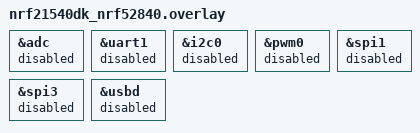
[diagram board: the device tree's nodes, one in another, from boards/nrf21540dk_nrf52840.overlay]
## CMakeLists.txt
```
#
# Copyright (c) 2021 Nordic Semiconductor ASA
#
# SPDX-License-Identifier: LicenseRef-Nordic-5-Clause
#

cmake_minimum_required(VERSION 3.20.0)

find_package(Zephyr HINTS $ENV{ZEPHYR_BASE})

project(matter-light-switch)

# Enable GNU STD support.
include(${ZEPHYR_CONNECTEDHOMEIP_MODULE_DIR}/config/nrfconnect/app/enable-gnu-std.cmake)

# NORDIC SDK APP START

# Include all source files that are located in the Matter common directory.
include(${ZEPHYR_NRF_MODULE_DIR}/samples/matter/common/cmake/source_common.cmake)

# Include Data Model utils
include(${ZEPHYR_NRF_MODULE_DIR}/samples/matter/common/cmake/data_model.cmake)

include(${ZEPHYR_NRF_MODULE_DIR}/samples/matter/common/cmake/zap_helpers.cmake)
ncs_get_zap_parent_dir(ZAP_PARENT_DIR)

target_include_directories(app PRIVATE
    src
    ${ZAP_PARENT_DIR}
)

target_compile_options(app PRIVATE -Wno-deprecated-declarations)

target_sources(app PRIVATE
    src/app_task.cpp
    src/light_switch.cpp
    src/main.cpp
    src/shell_commands.cpp
    ${ZEPHYR_NRF_MODULE_DIR}/samples/matter/common/src/binding/binding_handler.cpp
)

ncs_configure_data_model()
# NORDIC SDK APP END
```

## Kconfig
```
#
# Copyright (c) 2022 Nordic Semiconductor
#
# SPDX-License-Identifier: LicenseRef-Nordic-5-Clause
#
mainmenu "Matter nRF Connect Light Switch Example Application"

config STATE_LEDS
	bool "Use LEDs to indicate the device state"
	default y
	help
	  Use LEDs to render the current state of the device such as the progress of commissioning of
	  the device into a network or the factory reset initiation. Note that setting this option to
	  'n' does not disable the LED indicating the state of the simulated bolt.

# Sample configuration used for Thread networking
if OPENTHREAD

choice OPENTHREAD_NORDIC_LIBRARY_CONFIGURATION
	default OPENTHREAD_NORDIC_LIBRARY_MTD
endchoice

choice OPENTHREAD_DEVICE_TYPE
	default OPENTHREAD_MTD
endchoice

config CHIP_ENABLE_ICD_SUPPORT
	default y

# Reduce Thread TX output power to 0 dBm for SED device
config OPENTHREAD_DEFAULT_TX_POWER
	int
	default 0

endif # OPENTHREAD

if CHIP_WIFI

config NRF_WIFI_LOW_POWER
	default y

endif # CHIP_WIFI

# Enable Read Client functionality for all build configurations.
config CHIP_ENABLE_READ_CLIENT
	default y

source "${ZEPHYR_CONNECTEDHOMEIP_MODULE_DIR}/config/nrfconnect/chip-module/Kconfig.features"
source "${ZEPHYR_CONNECTEDHOMEIP_MODULE_DIR}/config/nrfconnect/chip-module/Kconfig.defaults"
source "${ZEPHYR_NRF_MODULE_DIR}/samples/matter/common/src/Kconfig"
source "Kconfig.zephyr"
```

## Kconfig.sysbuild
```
#
# Copyright (c) 2023 Nordic Semiconductor ASA
#
# SPDX-License-Identifier: LicenseRef-Nordic-5-Clause
#

config WIFI_NRF70
	default y if BOARD_NRF7002DK

#### Radio core selection
config NRF_DEFAULT_IPC_RADIO
	default y

# Enable IEEE802.15.4 serialization to network core
# This config automatically pulls in the `overlay-802154.conf` in the ipc_radio image
config NETCORE_IPC_RADIO_IEEE802154
	default y if SOC_SERIES_NRF53X && !WIFI_NRF70

# Enable Bluetooth serialization to network core
# This config automatically pulls in the `overlay-bt_hci_ipc.conf` in the ipc_radio image
config NETCORE_IPC_RADIO_BT_HCI_IPC
	default y if SOC_SERIES_NRF53X

#### Bootloader
choice BOOTLOADER
	default BOOTLOADER_MCUBOOT if !BOARD_NRF21540DK
endchoice

if BOOTLOADER_MCUBOOT

#### DFU multi-image support
config DFU_MULTI_IMAGE_PACKAGE_BUILD
	default y

config DFU_MULTI_IMAGE_PACKAGE_APP
	default y

config PM_EXTERNAL_FLASH_MCUBOOT_SECONDARY
	default y

#### DFU network core configuration
if SOC_SERIES_NRF53X

config MCUBOOT_UPDATEABLE_IMAGES
	default 2

choice MCUBOOT_MODE
	default MCUBOOT_MODE_OVERWRITE_ONLY
endchoice

choice BOOT_SIGNATURE_TYPE
	default BOOT_SIGNATURE_TYPE_RSA
endchoice

config SECURE_BOOT_NETCORE
	default y

config NETCORE_APP_UPDATE
	default y

config DFU_MULTI_IMAGE_PACKAGE_NET
	default y

endif # SOC_SERIES_NRF53X

if BOARD_NRF54L15DK

config PM_OVERRIDE_EXTERNAL_DRIVER_CHECK
	default y

endif # BOARD_NRF54L15DK

endif # BOOTLOADER_MCUBOOT

#### Enable generating factory data
config MATTER_FACTORY_DATA_GENERATE
	default y if !BOARD_NRF21540DK

source "share/sysbuild/Kconfig"
```

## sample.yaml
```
sample:
  description: Matter Light Switch example
  name: Matter Light Switch
tests:
  sample.matter.light_switch.debug:
    sysbuild: true
    build_only: true
    integration_platforms:
      - nrf52840dk/nrf52840
      - nrf5340dk/nrf5340/cpuapp
      - nrf7002dk/nrf5340/cpuapp
      - nrf54l15dk/nrf54l15/cpuapp
      - nrf54l15dk/nrf54l15/cpuapp/ns
      - nrf54lm20pdk/nrf54lm20a/cpuapp
    platform_allow:
      - nrf52840dk/nrf52840
      - nrf5340dk/nrf5340/cpuapp
      - nrf7002dk/nrf5340/cpuapp
      - nrf54l15dk/nrf54l15/cpuapp
      - nrf54l15dk/nrf54l15/cpuapp/ns
      - nrf54lm20pdk/nrf54lm20a/cpuapp
    tags:
      - sysbuild
      - ci_samples_matter
  sample.matter.light_switch.release:
    sysbuild: true
    build_only: true
    extra_args:
      - FILE_SUFFIX=release
      - SB_CONFIG_BOOTLOADER_MCUBOOT=y
      - SB_CONFIG_PARTITION_MANAGER=y
    integration_platforms:
      - nrf52840dk/nrf52840
      - nrf5340dk/nrf5340/cpuapp
      - nrf7002dk/nrf5340/cpuapp
      - nrf54l15dk/nrf54l15/cpuapp
      - nrf54lm20pdk/nrf54lm20a/cpuapp
    platform_allow:
      - nrf52840dk/nrf52840
      - nrf5340dk/nrf5340/cpuapp
      - nrf7002dk/nrf5340/cpuapp
      - nrf54l15dk/nrf54l15/cpuapp
      - nrf54lm20pdk/nrf54lm20a/cpuapp
    tags:
      - sysbuild
      - ci_samples_matter
  sample.matter.light_switch.lit_icd:
    sysbuild: true
    build_only: true
    extra_args:
      - light_switch_SNIPPET=lit_icd
    integration_platforms:
      - nrf52840dk/nrf52840
      - nrf5340dk/nrf5340/cpuapp
      - nrf54l15dk/nrf54l15/cpuapp
    platform_allow:
      - nrf52840dk/nrf52840
      - nrf5340dk/nrf5340/cpuapp
      - nrf54l15dk/nrf54l15/cpuapp
    tags:
      - sysbuild
      - ci_samples_matter
  # Sample to execute load tests
  sample.matter.light_switch.persistent_subscriptions:
    sysbuild: true
    build_only: true
    extra_args:
      - CONFIG_CHIP_PERSISTENT_SUBSCRIPTIONS=y
      - CONFIG_WIFI_NM_WPA_SUPPLICANT_WPA3=n
    platform_allow:
      - nrf52840dk/nrf52840
      - nrf5340dk/nrf5340/cpuapp
      - nrf7002dk/nrf5340/cpuapp
      - nrf54l15dk/nrf54l15/cpuapp
    integration_platforms:
      - nrf52840dk/nrf52840
      - nrf5340dk/nrf5340/cpuapp
      - nrf7002dk/nrf5340/cpuapp
      - nrf54l15dk/nrf54l15/cpuapp
    tags:
      - sysbuild
      - ci_samples_matter
```

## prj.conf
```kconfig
#
# Copyright (c) 2021 Nordic Semiconductor ASA
#
# SPDX-License-Identifier: LicenseRef-Nordic-5-Clause
#

# Enable CHIP
CONFIG_CHIP=y
CONFIG_CHIP_PROJECT_CONFIG="src/chip_project_config.h"

# Configure ZAP file name
CONFIG_NCS_SAMPLE_MATTER_ZAP_FILE_PATH="${APPLICATION_CONFIG_DIR}/src/default_zap/light_switch.zap"

# 32772 == 0x8004 (example light-switch-app)
CONFIG_CHIP_DEVICE_PRODUCT_ID=32772
CONFIG_STD_CPP17=y

# Enable Matter pairing automatically on application start.
CONFIG_CHIP_ENABLE_PAIRING_AUTOSTART=y

# Enable Matter extended announcement and increase duration to 1 hour.
CONFIG_CHIP_BLE_EXT_ADVERTISING=y
CONFIG_CHIP_BLE_ADVERTISING_DURATION=60

# Add support for LEDs and buttons on Nordic development kits
CONFIG_DK_LIBRARY=y

# Bluetooth Low Energy configuration
CONFIG_BT_DEVICE_NAME="MatterSwitch"

# Suspend devices when the CPU goes into sleep
CONFIG_PM_DEVICE=y

# Other settings
CONFIG_THREAD_NAME=y
CONFIG_MPU_STACK_GUARD=y
CONFIG_RESET_ON_FATAL_ERROR=n
CONFIG_CHIP_LIB_SHELL=y
CONFIG_NCS_SAMPLE_MATTER_TEST_SHELL=y

# Reduce application size
CONFIG_USE_SEGGER_RTT=n

# Enable Factory Data feature
CONFIG_CHIP_FACTORY_DATA=y
CONFIG_CHIP_FACTORY_DATA_BUILD=y
```

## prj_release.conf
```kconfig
#
# Copyright (c) 2021 Nordic Semiconductor ASA
#
# SPDX-License-Identifier: LicenseRef-Nordic-5-Clause
#

# Enable CHIP
CONFIG_CHIP=y
CONFIG_CHIP_PROJECT_CONFIG="src/chip_project_config.h"

# Configure ZAP file name
CONFIG_NCS_SAMPLE_MATTER_ZAP_FILE_PATH="${APPLICATION_CONFIG_DIR}/src/default_zap/light_switch.zap"

# 32772 == 0x8004 (example light-switch-app)
CONFIG_CHIP_DEVICE_PRODUCT_ID=32772
CONFIG_STD_CPP17=y

# Enable Matter pairing automatically on application start.
CONFIG_CHIP_ENABLE_PAIRING_AUTOSTART=y

# Enable Matter extended announcement and increase duration to 1 hour.
CONFIG_CHIP_BLE_EXT_ADVERTISING=y
CONFIG_CHIP_BLE_ADVERTISING_DURATION=60

# Add support for LEDs and buttons on Nordic development kits
CONFIG_DK_LIBRARY=y

# Try to disable unused RAM blocks to reduce power consumption
CONFIG_RAM_POWER_DOWN_LIBRARY=y

# Bluetooth Low Energy configuration
CONFIG_BT_DEVICE_NAME="MatterSwitch"

# Suspend devices when the CPU goes into sleep
CONFIG_PM_DEVICE=y

# Enable system reset on fatal error
CONFIG_RESET_ON_FATAL_ERROR=y

# Disable all debug features
CONFIG_USE_SEGGER_RTT=n
CONFIG_SHELL=n
CONFIG_OPENTHREAD_SHELL=n
CONFIG_CONSOLE=n
CONFIG_UART_CONSOLE=n
CONFIG_SERIAL=n
CONFIG_LOG=n
CONFIG_LOG_MODE_MINIMAL=n
CONFIG_ASSERT_VERBOSE=n
CONFIG_ASSERT_NO_FILE_INFO=y
CONFIG_PRINTK=n
CONFIG_PRINTK_SYNC=n
CONFIG_THREAD_NAME=n
CONFIG_BOOT_BANNER=n

# Enable Factory Data feature
CONFIG_CHIP_FACTORY_DATA=y
CONFIG_CHIP_FACTORY_DATA_BUILD=y

# Enable Watchdog
CONFIG_NCS_SAMPLE_MATTER_WATCHDOG=y

# Enable LTO to decrease the flash usage.
CONFIG_LTO=y
CONFIG_ISR_TABLES_LOCAL_DECLARATION=y
```

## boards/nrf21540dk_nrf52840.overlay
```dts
/* Copyright (c) 2021 Nordic Semiconductor ASA
 *
 * SPDX-License-Identifier: LicenseRef-Nordic-5-Clause
 */

/* Disable unused peripherals to reduce power consumption */
&adc {
	status = "disabled";
};
&uart1 {
	status = "disabled";
};
&i2c0 {
	status = "disabled";
};
&pwm0 {
	status = "disabled";
};
&spi1 {
	status = "disabled";
};
&spi3 {
	status = "disabled";
};
&usbd {
	status = "disabled";
};
```

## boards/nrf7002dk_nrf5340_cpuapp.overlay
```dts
/*
 * Copyright (c) 2021 Nordic Semiconductor ASA
 *
 * SPDX-License-Identifier: LicenseRef-Nordic-5-Clause
 */

#include <zephyr/dt-bindings/ipc_service/static_vrings.h>

/ {
	chosen {
		nordic,pm-ext-flash = &mx25r64;
	};

	aliases {
		watchdog0 = &wdt0;
	};
};

/* Set IPC thread priority to the highest value to not collide with other threads. */
&ipc0 {
	zephyr,priority = <0 PRIO_COOP>;
};
```

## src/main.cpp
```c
/*
 * Copyright (c) 2022 Nordic Semiconductor ASA
 *
 * SPDX-License-Identifier: LicenseRef-Nordic-5-Clause
 */

#include "app_task.h"

#include <cstdlib>
#include <zephyr/logging/log.h>

LOG_MODULE_REGISTER(app, CONFIG_CHIP_APP_LOG_LEVEL);

int main()
{
	CHIP_ERROR err = AppTask::Instance().StartApp();

	LOG_ERR("Exited with code %" CHIP_ERROR_FORMAT, err.Format());
	return err == CHIP_NO_ERROR ? EXIT_SUCCESS : EXIT_FAILURE;
}
```

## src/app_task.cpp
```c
/*
 * Copyright (c) 2022 Nordic Semiconductor ASA
 *
 * SPDX-License-Identifier: LicenseRef-Nordic-5-Clause
 */

#include "app_task.h"

#include "light_switch.h"

#include "app/matter_init.h"
#include "app/task_executor.h"
#include "board/board.h"

#include <app/clusters/identify-server/identify-server.h>
#include <setup_payload/OnboardingCodesUtil.h>

#include <zephyr/logging/log.h>

LOG_MODULE_DECLARE(app, CONFIG_CHIP_APP_LOG_LEVEL);

using namespace ::chip;
using namespace ::chip::app;
using namespace ::chip::DeviceLayer;

namespace
{
constexpr uint32_t kDimmerTriggeredTimeout = 500;
constexpr uint32_t kDimmerInterval = 300;
constexpr EndpointId kLightSwitchEndpointId = 1;
constexpr EndpointId kLightEndpointId = 1;

k_timer sDimmerPressKeyTimer;
k_timer sDimmerTimer;

Identify sIdentify = { kLightEndpointId, AppTask::IdentifyStartHandler, AppTask::IdentifyStopHandler,
		       Clusters::Identify::IdentifyTypeEnum::kVisibleIndicator };
bool sWasDimmerTriggered = false;

#define APPLICATION_BUTTON_MASK DK_BTN2_MSK

#ifdef CONFIG_CHIP_ICD_UAT_SUPPORT
#define UAT_BUTTON_MASK DK_BTN3_MSK
#endif
} /* namespace */

void AppTask::DimmerTriggerEventHandler()
{
	if (!sWasDimmerTriggered) {
		LightSwitch::GetInstance().InitiateActionSwitch(LightSwitch::Action::Toggle);
	}

	Instance().CancelTimer(Timer::Dimmer);
	Instance().CancelTimer(Timer::DimmerTrigger);
	sWasDimmerTriggered = false;
}

void AppTask::TimerEventHandler(const Timer &timerType)
{
	switch (timerType) {
	case Timer::DimmerTrigger:
		LOG_INF("Dimming started...");
		sWasDimmerTriggered = true;
		LightSwitch::GetInstance().InitiateActionSwitch(LightSwitch::Action::On);
		Instance().StartTimer(Timer::Dimmer, kDimmerInterval);
		Instance().CancelTimer(Timer::DimmerTrigger);
		break;
	case Timer::Dimmer:
		LightSwitch::GetInstance().DimmerChangeBrightness();
		break;
	default:
		break;
	}
}

void AppTask::IdentifyStartHandler(Identify *)
{
	Nrf::PostTask(
		[] { Nrf::GetBoard().GetLED(Nrf::DeviceLeds::LED2).Blink(Nrf::LedConsts::kIdentifyBlinkRate_ms); });
}

void AppTask::IdentifyStopHandler(Identify *)
{
	Nrf::PostTask([] { Nrf::GetBoard().GetLED(Nrf::DeviceLeds::LED2).Set(false); });
}

void AppTask::ButtonEventHandler(Nrf::ButtonState state, Nrf::ButtonMask hasChanged)
{
	if ((APPLICATION_BUTTON_MASK & state & hasChanged)) {
		LOG_INF("Button has been pressed, keep in this state for at least 500 ms to change light sensitivity of bound lighting devices.");
		Instance().StartTimer(Timer::DimmerTrigger, kDimmerTriggeredTimeout);
	} else if ((APPLICATION_BUTTON_MASK & hasChanged)) {
		Nrf::PostTask([] { DimmerTriggerEventHandler(); });
#ifdef CONFIG_CHIP_ICD_UAT_SUPPORT
	} else if ((UAT_BUTTON_MASK & state & hasChanged)) {
		LOG_INF("ICD UserActiveMode has been triggered.");
		Server::GetInstance().GetICDManager().OnNetworkActivity();
#endif
	}
}

void AppTask::StartTimer(Timer timer, uint32_t timeoutMs)
{
	switch (timer) {
	case Timer::DimmerTrigger:
		k_timer_start(&sDimmerPressKeyTimer, K_MSEC(timeoutMs), K_NO_WAIT);
		break;
	case Timer::Dimmer:
		k_timer_start(&sDimmerTimer, K_MSEC(timeoutMs), K_MSEC(timeoutMs));
		break;
	default:
		break;
	}
}

void AppTask::CancelTimer(Timer timer)
{
	switch (timer) {
	case Timer::DimmerTrigger:
		k_timer_stop(&sDimmerPressKeyTimer);
		break;
	case Timer::Dimmer:
		k_timer_stop(&sDimmerTimer);
		break;
	default:
		break;
	}
}

void AppTask::UserTimerTimeoutCallback(k_timer *timer)
{
	if (!timer) {
		return;
	}
	Timer timerType;

	if (timer == &sDimmerPressKeyTimer) {
		timerType = Timer::DimmerTrigger;
	} else if (timer == &sDimmerTimer) {
		timerType = Timer::Dimmer;
	} else {
		return;
	}

	Nrf::PostTask([timerType]() { TimerEventHandler(timerType); });
}

CHIP_ERROR AppTask::Init()
{
	/* Initialize Matter stack */
	ReturnErrorOnFailure(Nrf::Matter::PrepareServer(Nrf::Matter::InitData{ .mPostServerInitClbk = [] {
		LightSwitch::GetInstance().Init(kLightSwitchEndpointId);
		return CHIP_NO_ERROR;
	} }));

	/* Initialize application timers */
	k_timer_init(&sDimmerPressKeyTimer, AppTask::UserTimerTimeoutCallback, nullptr);
	k_timer_init(&sDimmerTimer, AppTask::UserTimerTimeoutCallback, nullptr);

	if (!Nrf::GetBoard().Init(ButtonEventHandler)) {
		LOG_ERR("User interface initialization failed.");
		return CHIP_ERROR_INCORRECT_STATE;
	}

	/* Register Matter event handler that controls the connectivity status LED based on the captured Matter network
	 * state. */
	ReturnErrorOnFailure(Nrf::Matter::RegisterEventHandler(Nrf::Board::DefaultMatterEventHandler, 0));

	return Nrf::Matter::StartServer();
}

CHIP_ERROR AppTask::StartApp()
{
	ReturnErrorOnFailure(Init());

	while (true) {
		Nrf::DispatchNextTask();
	}

	return CHIP_NO_ERROR;
}
```

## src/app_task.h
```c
/*
 * Copyright (c) 2022 Nordic Semiconductor ASA
 *
 * SPDX-License-Identifier: LicenseRef-Nordic-5-Clause
 */

#pragma once

#include "board/board.h"

#include <platform/CHIPDeviceLayer.h>

struct k_timer;
struct Identify;

class AppTask {
public:
	static AppTask &Instance()
	{
		static AppTask sAppTask;
		return sAppTask;
	};

	CHIP_ERROR StartApp();

	void UpdateClusterState();

	static void IdentifyStartHandler(Identify *);
	static void IdentifyStopHandler(Identify *);

private:
	enum Timer : uint8_t { DimmerTrigger, Dimmer };

	CHIP_ERROR Init();

	static void DimmerTriggerEventHandler();
	static void TimerEventHandler(const Timer &event);
	static void ButtonEventHandler(Nrf::ButtonState state, Nrf::ButtonMask hasChanged);

	static void StartTimer(Timer, uint32_t);
	static void CancelTimer(Timer);
	static void UserTimerTimeoutCallback(k_timer *timer);
};
```

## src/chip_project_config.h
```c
/*
 * Copyright (c) 2022 Nordic Semiconductor ASA
 *
 * SPDX-License-Identifier: LicenseRef-Nordic-5-Clause
 */

#pragma once

#define CHIP_CONFIG_CONTROLLER_MAX_ACTIVE_DEVICES 2
```

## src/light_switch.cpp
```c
/*
 * Copyright (c) 2022 Nordic Semiconductor ASA
 *
 * SPDX-License-Identifier: LicenseRef-Nordic-5-Clause
 */

#include "light_switch.h"
#include "binding/binding_handler.h"

#ifdef CONFIG_CHIP_LIB_SHELL
#include "shell_commands.h"
#endif

#include <app/server/Server.h>
#include <app/util/binding-table.h>
#include <controller/InvokeInteraction.h>
#include <platform/CHIPDeviceLayer.h>
#include <zephyr/logging/log.h>

using namespace chip;
using namespace chip::app;

LOG_MODULE_DECLARE(app, CONFIG_CHIP_APP_LOG_LEVEL);

void LightSwitch::Init(chip::EndpointId lightSwitchEndpoint)
{
	Nrf::Matter::BindingHandler::Init();
#ifdef CONFIG_CHIP_LIB_SHELL
	SwitchCommands::RegisterSwitchCommands();
#endif
	mLightSwitchEndpoint = lightSwitchEndpoint;
}

void LightSwitch::InitiateActionSwitch(Action action)
{
	Nrf::Matter::BindingHandler::BindingData *data =
		Platform::New<Nrf::Matter::BindingHandler::BindingData>();
	if (data) {
		data->EndpointId = mLightSwitchEndpoint;
		data->ClusterId = Clusters::OnOff::Id;
		data->InvokeCommandFunc = SwitchChangedHandler;
		switch (action) {
		case Action::Toggle:
			data->CommandId = Clusters::OnOff::Commands::Toggle::Id;
			break;
		case Action::On:
			data->CommandId = Clusters::OnOff::Commands::On::Id;
			break;
		case Action::Off:
			data->CommandId = Clusters::OnOff::Commands::Off::Id;
			break;
		default:
			Platform::Delete(data);
			return;
		}
		Nrf::Matter::BindingHandler::RunBoundClusterAction(data);
	}
}

void LightSwitch::DimmerChangeBrightness()
{
	static uint16_t sBrightness;
	Nrf::Matter::BindingHandler::BindingData *data =
		Platform::New<Nrf::Matter::BindingHandler::BindingData>();
	if (data) {
		data->EndpointId = mLightSwitchEndpoint;
		data->CommandId = Clusters::LevelControl::Commands::MoveToLevel::Id;
		data->ClusterId = Clusters::LevelControl::Id;
		data->InvokeCommandFunc = SwitchChangedHandler;
		/* add to brightness 3 to approximate 1% step of brightness after each call dimmer change. */
		sBrightness += kOnePercentBrightnessApproximation;
		if (sBrightness > kMaximumBrightness) {
			sBrightness = 0;
		}
		data->Value = (uint8_t)sBrightness;
		Nrf::Matter::BindingHandler::RunBoundClusterAction(data);
	}
}

void LightSwitch::SwitchChangedHandler(const EmberBindingTableEntry &binding, OperationalDeviceProxy *deviceProxy,
				       Nrf::Matter::BindingHandler::BindingData &bindingData)
{
	if (binding.type == MATTER_MULTICAST_BINDING) {
		switch (bindingData.ClusterId) {
		case Clusters::OnOff::Id:
			OnOffProcessCommand(bindingData.CommandId, binding, nullptr, bindingData);
			break;
		case Clusters::LevelControl::Id:
			LevelControlProcessCommand(bindingData.CommandId, binding, nullptr, bindingData);
			break;
		default:
			ChipLogError(NotSpecified, "Invalid binding group command data");
			break;
		}
	} else if (binding.type == MATTER_UNICAST_BINDING) {
		switch (bindingData.ClusterId) {
		case Clusters::OnOff::Id:
			OnOffProcessCommand(bindingData.CommandId, binding, deviceProxy, bindingData);
			break;
		case Clusters::LevelControl::Id:
			LevelControlProcessCommand(bindingData.CommandId, binding, deviceProxy, bindingData);
			break;
		default:
			ChipLogError(NotSpecified, "Invalid binding unicast command data");
			break;
		}
	}
}

void LightSwitch::OnOffProcessCommand(CommandId commandId, const EmberBindingTableEntry &binding,
				      OperationalDeviceProxy *device,
				      Nrf::Matter::BindingHandler::BindingData &bindingData)
{
	CHIP_ERROR ret = CHIP_NO_ERROR;

	auto onSuccess = [dataPointer = Platform::New<Nrf::Matter::BindingHandler::BindingData>(bindingData)](
				 const ConcreteCommandPath &commandPath, const StatusIB &status,
				 const auto &dataResponse) {
		Nrf::Matter::BindingHandler::OnInvokeCommandSucces(dataPointer);
	};

	auto onFailure = [dataPointer = Platform::New<Nrf::Matter::BindingHandler::BindingData>(bindingData)](
				 CHIP_ERROR aError) mutable {
		Nrf::Matter::BindingHandler::OnInvokeCommandFailure(dataPointer, aError);
	};

	if (device) {
		/* We are validating connection is ready once here instead of multiple times in each case
		 * statement below. */
		VerifyOrDie(device->ConnectionReady());
	}

	switch (commandId) {
	case Clusters::OnOff::Commands::Toggle::Id:
		Clusters::OnOff::Commands::Toggle::Type toggleCommand;
		if (device) {
			ret = Controller::InvokeCommandRequest(device->GetExchangeManager(),
							       device->GetSecureSession().Value(), binding.remote,
							       toggleCommand, onSuccess, onFailure);
		} else {
			Messaging::ExchangeManager &exchangeMgr = Server::GetInstance().GetExchangeManager();
			ret = Controller::InvokeGroupCommandRequest(&exchangeMgr, binding.fabricIndex, binding.groupId,
								    toggleCommand);
		}
		break;

	case Clusters::OnOff::Commands::On::Id:
		Clusters::OnOff::Commands::On::Type onCommand;
		if (device) {
			ret = Controller::InvokeCommandRequest(device->GetExchangeManager(),
							       device->GetSecureSession().Value(), binding.remote,
							       onCommand, onSuccess, onFailure);
		} else {
			Messaging::ExchangeManager &exchangeMgr = Server::GetInstance().GetExchangeManager();
			ret = Controller::InvokeGroupCommandRequest(&exchangeMgr, binding.fabricIndex, binding.groupId,
								    onCommand);
		}
		break;

	case Clusters::OnOff::Commands::Off::Id:
		Clusters::OnOff::Commands::Off::Type offCommand;
		if (device) {
			ret = Controller::InvokeCommandRequest(device->GetExchangeManager(),
							       device->GetSecureSession().Value(), binding.remote,
							       offCommand, onSuccess, onFailure);
		} else {
			Messaging::ExchangeManager &exchangeMgr = Server::GetInstance().GetExchangeManager();
			ret = Controller::InvokeGroupCommandRequest(&exchangeMgr, binding.fabricIndex, binding.groupId,
								    offCommand);
		}
		break;
	default:
		LOG_DBG("Invalid binding command data - commandId is not supported");
		break;
	}
	if (CHIP_NO_ERROR != ret) {
		LOG_ERR("Invoke OnOff Command Request ERROR: %s", ErrorStr(ret));
	}
}

void LightSwitch::LevelControlProcessCommand(CommandId commandId, const EmberBindingTableEntry &binding,
					     OperationalDeviceProxy *device,
					     Nrf::Matter::BindingHandler::BindingData &bindingData)
{
	auto onSuccess = [dataPointer = Platform::New<Nrf::Matter::BindingHandler::BindingData>(bindingData)](
				 const ConcreteCommandPath &commandPath, const StatusIB &status,
				 const auto &dataResponse) {
		Nrf::Matter::BindingHandler::OnInvokeCommandSucces(dataPointer);
	};

	auto onFailure = [dataPointer = Platform::New<Nrf::Matter::BindingHandler::BindingData>(bindingData)](
				 CHIP_ERROR aError) mutable {
		Nrf::Matter::BindingHandler::OnInvokeCommandFailure(dataPointer, aError);
	};

	CHIP_ERROR ret = CHIP_NO_ERROR;

	if (device) {
		/* We are validating connection is ready once here instead of multiple times in each case
		 * statement below. */
		VerifyOrDie(device->ConnectionReady());
	}

	switch (commandId) {
	case Clusters::LevelControl::Commands::MoveToLevel::Id: {
		Clusters::LevelControl::Commands::MoveToLevel::Type moveToLevelCommand;
		moveToLevelCommand.level = bindingData.Value;
		if (device) {
			ret = Controller::InvokeCommandRequest(device->GetExchangeManager(),
							       device->GetSecureSession().Value(), binding.remote,
							       moveToLevelCommand, onSuccess, onFailure);
		} else {
			Messaging::ExchangeManager &exchangeMgr = Server::GetInstance().GetExchangeManager();
			ret = Controller::InvokeGroupCommandRequest(&exchangeMgr, binding.fabricIndex, binding.groupId,
								    moveToLevelCommand);
		}
	} break;
	default:
		LOG_DBG("Invalid binding command data - commandId is not supported");
		break;
	}
	if (CHIP_NO_ERROR != ret) {
		LOG_ERR("Invoke Group Command Request ERROR: %s", ErrorStr(ret));
	}
}
```

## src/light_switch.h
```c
/*
 * Copyright (c) 2022 Nordic Semiconductor ASA
 *
 * SPDX-License-Identifier: LicenseRef-Nordic-5-Clause
 */

#pragma once
#include <app/util/basic-types.h>
#include <lib/core/CHIPError.h>

#include "binding/binding_handler.h"

#include <atomic>

/** @class LightSwitch
 *  @brief Class for controlling a CHIP light bulb over a Thread network
 *
 *  Features:
 *  - discovering a CHIP light bulb which advertises itself by sending Thread multicast packets
 *  - toggling and dimming the connected CHIP light bulb by sending appropriate CHIP messages
 */
class LightSwitch {
public:
	enum class Action : uint8_t {
		Toggle, /* Switch state on lighting-app device */
		On, /* Turn on light on lighting-app device */
		Off /* Turn off light on lighting-app device */
	};

	void Init(chip::EndpointId lightSwitchEndpoint);
	void InitiateActionSwitch(Action action);
	void DimmerChangeBrightness();
	chip::EndpointId GetLightSwitchEndpointId() { return mLightSwitchEndpoint; }
	static void SwitchChangedHandler(const EmberBindingTableEntry &binding,
					 chip::OperationalDeviceProxy *deviceProxy,
					 Nrf::Matter::BindingHandler::BindingData &bindingData);

	static LightSwitch &GetInstance()
	{
		static LightSwitch sLightSwitch;
		return sLightSwitch;
	}

private:
	static void OnOffProcessCommand(chip::CommandId commandId, const EmberBindingTableEntry &binding,
					chip::OperationalDeviceProxy *device,
					Nrf::Matter::BindingHandler::BindingData &bindingData);
	static void LevelControlProcessCommand(chip::CommandId commandId, const EmberBindingTableEntry &binding,
					       chip::OperationalDeviceProxy *device,
					       Nrf::Matter::BindingHandler::BindingData &bindingData);
	constexpr static auto kOnePercentBrightnessApproximation = 3;
	constexpr static auto kMaximumBrightness = 254;

	chip::EndpointId mLightSwitchEndpoint;
};
```

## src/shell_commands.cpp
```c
/*
 * Copyright (c) 2022 Nordic Semiconductor ASA
 *
 * SPDX-License-Identifier: LicenseRef-Nordic-5-Clause
 */

#include "shell_commands.h"
#include "binding/binding_handler.h"
#include "light_switch.h"

#include <platform/CHIPDeviceLayer.h>

#ifdef CONFIG_CHIP_LIB_SHELL

using namespace chip;
using namespace chip::app;

namespace SwitchCommands
{
using Shell::Engine;
using Shell::shell_command_t;
using Shell::streamer_get;
using Shell::streamer_printf;

Engine sShellSwitchSubCommands;
Engine sShellSwitchOnOffSubCommands;
Engine sShellSwitchGroupsSubCommands;
Engine sShellSwitchGroupsOnOffSubCommands;

static CHIP_ERROR SwitchHelpHandler(int argc, char **argv)
{
	sShellSwitchSubCommands.ForEachCommand(Shell::PrintCommandHelp, nullptr);
	return CHIP_NO_ERROR;
}

static CHIP_ERROR SwitchCommandHandler(int argc, char **argv)
{
	if (argc == 0) {
		return SwitchHelpHandler(argc, argv);
	}
	return sShellSwitchSubCommands.ExecCommand(argc, argv);
}

static CHIP_ERROR TableCommandHelper(int argc, char **argv)
{
	Nrf::Matter::BindingHandler::PrintBindingTable();
	return CHIP_NO_ERROR;
}

namespace Unicast
{
	static CHIP_ERROR OnOffHelpHandler(int argc, char **argv)
	{
		sShellSwitchOnOffSubCommands.ForEachCommand(Shell::PrintCommandHelp, nullptr);
		return CHIP_NO_ERROR;
	}

	static CHIP_ERROR OnOffCommandHandler(int argc, char **argv)
	{
		if (argc == 0) {
			return OnOffHelpHandler(argc, argv);
		}
		return sShellSwitchOnOffSubCommands.ExecCommand(argc, argv);
	}

	static CHIP_ERROR OnCommandHandler(int argc, char **argv)
	{
		Nrf::Matter::BindingHandler::BindingData *data =
			Platform::New<Nrf::Matter::BindingHandler::BindingData>();
		if (data) {
			data->EndpointId = LightSwitch::GetInstance().GetLightSwitchEndpointId();
			data->CommandId = Clusters::OnOff::Commands::On::Id;
			data->ClusterId = Clusters::OnOff::Id;
			data->InvokeCommandFunc = LightSwitch::SwitchChangedHandler;
			data->IsGroup.SetValue(false);

			Nrf::Matter::BindingHandler::RunBoundClusterAction(data);
			return CHIP_NO_ERROR;
		}
		return CHIP_ERROR_NO_MEMORY;
	}

	static CHIP_ERROR OffCommandHandler(int argc, char **argv)
	{
		Nrf::Matter::BindingHandler::BindingData *data =
			Platform::New<Nrf::Matter::BindingHandler::BindingData>();
		if (data) {
			data->EndpointId = LightSwitch::GetInstance().GetLightSwitchEndpointId();
			data->CommandId = Clusters::OnOff::Commands::Off::Id;
			data->ClusterId = Clusters::OnOff::Id;
			data->InvokeCommandFunc = LightSwitch::SwitchChangedHandler;
			data->IsGroup.SetValue(false);

			Nrf::Matter::BindingHandler::RunBoundClusterAction(data);
			return CHIP_NO_ERROR;
		}
		return CHIP_ERROR_NO_MEMORY;
	}

	static CHIP_ERROR ToggleCommandHandler(int argc, char **argv)
	{
		Nrf::Matter::BindingHandler::BindingData *data =
			Platform::New<Nrf::Matter::BindingHandler::BindingData>();
		if (data) {
			data->EndpointId = LightSwitch::GetInstance().GetLightSwitchEndpointId();
			data->CommandId = Clusters::OnOff::Commands::Toggle::Id;
			data->ClusterId = Clusters::OnOff::Id;
			data->InvokeCommandFunc = LightSwitch::SwitchChangedHandler;
			data->IsGroup.SetValue(false);

			Nrf::Matter::BindingHandler::RunBoundClusterAction(data);
			return CHIP_NO_ERROR;
		}
		return CHIP_ERROR_NO_MEMORY;
	}
} /* namespace Unicast */

namespace Group
{
	CHIP_ERROR SwitchHelpHandler(int argc, char **argv)
	{
		sShellSwitchGroupsSubCommands.ForEachCommand(Shell::PrintCommandHelp, nullptr);
		return CHIP_NO_ERROR;
	}

	CHIP_ERROR SwitchCommandHandler(int argc, char **argv)
	{
		if (argc == 0) {
			return SwitchHelpHandler(argc, argv);
		}

		return sShellSwitchGroupsSubCommands.ExecCommand(argc, argv);
	}

	static CHIP_ERROR OnOffHelpHandler(int argc, char **argv)
	{
		sShellSwitchGroupsOnOffSubCommands.ForEachCommand(Shell::PrintCommandHelp, nullptr);
		return CHIP_NO_ERROR;
	}

	static CHIP_ERROR OnOffCommandHandler(int argc, char **argv)
	{
		if (argc == 0) {
			return OnOffHelpHandler(argc, argv);
		}

		return sShellSwitchGroupsOnOffSubCommands.ExecCommand(argc, argv);
	}

	CHIP_ERROR OnCommandHandler(int argc, char **argv)
	{
		Nrf::Matter::BindingHandler::BindingData *data =
			Platform::New<Nrf::Matter::BindingHandler::BindingData>();
		if (data) {
			data->EndpointId = LightSwitch::GetInstance().GetLightSwitchEndpointId();
			data->CommandId = Clusters::OnOff::Commands::On::Id;
			data->ClusterId = Clusters::OnOff::Id;
			data->InvokeCommandFunc = LightSwitch::SwitchChangedHandler;
			data->IsGroup.SetValue(true);

			Nrf::Matter::BindingHandler::RunBoundClusterAction(data);
			return CHIP_NO_ERROR;
		}
		return CHIP_ERROR_NO_MEMORY;
	}

	CHIP_ERROR OffCommandHandler(int argc, char **argv)
	{
		Nrf::Matter::BindingHandler::BindingData *data =
			Platform::New<Nrf::Matter::BindingHandler::BindingData>();
		if (data) {
			data->EndpointId = LightSwitch::GetInstance().GetLightSwitchEndpointId();
			data->CommandId = Clusters::OnOff::Commands::Off::Id;
			data->ClusterId = Clusters::OnOff::Id;
			data->InvokeCommandFunc = LightSwitch::SwitchChangedHandler;
			data->IsGroup.SetValue(true);

			Nrf::Matter::BindingHandler::RunBoundClusterAction(data);
			return CHIP_NO_ERROR;
		}
		return CHIP_ERROR_NO_MEMORY;
	}

	CHIP_ERROR ToggleCommandHandler(int argc, char **argv)
	{
		Nrf::Matter::BindingHandler::BindingData *data =
			Platform::New<Nrf::Matter::BindingHandler::BindingData>();
		if (data) {
			data->EndpointId = LightSwitch::GetInstance().GetLightSwitchEndpointId();
			data->CommandId = Clusters::OnOff::Commands::Toggle::Id;
			data->ClusterId = Clusters::OnOff::Id;
			data->InvokeCommandFunc = LightSwitch::SwitchChangedHandler;
			data->IsGroup.SetValue(true);

			Nrf::Matter::BindingHandler::RunBoundClusterAction(data);
			return CHIP_NO_ERROR;
		}
		return CHIP_ERROR_NO_MEMORY;
	}

} /* namespace Group */

void RegisterSwitchCommands()
{
	static const shell_command_t sSwitchSubCommands[] = {
		{ &SwitchHelpHandler, "help", "Switch commands" },
		{ &Unicast::OnOffCommandHandler, "onoff", "Usage: switch onoff [on|off|toggle]" },
		{ &Group::SwitchCommandHandler, "groups", "Usage: switch groups onoff [on|off|toggle]" },
		{ &TableCommandHelper, "table", "Print a binding table" }
	};

	static const shell_command_t sSwitchOnOffSubCommands[] = {
		{ &Unicast::OnOffHelpHandler, "help", "Usage : switch ononff [on|off|toggle]" },
		{ &Unicast::OnCommandHandler, "on", "Sends on command to bound lighting app" },
		{ &Unicast::OffCommandHandler, "off", "Sends off command to bound lighting app" },
		{ &Unicast::ToggleCommandHandler, "toggle", "Sends toggle command to bound lighting app" }
	};

	static const shell_command_t sSwitchGroupsSubCommands[] = {
		{ &Group::SwitchHelpHandler, "help", "switch a group of bounded lightning apps" },
		{ &Group::OnOffCommandHandler, "onoff", "Usage: switch groups onoff [on|off|toggle]" }
	};

	static const shell_command_t sSwichGroupsOnOffSubCommands[] = {
		{ &Group::OnOffHelpHandler, "help", "Usage: switch groups onoff [on|off|toggle]" },
		{ &Group::OnCommandHandler, "on", "Sends on command to bound Group" },
		{ &Group::OffCommandHandler, "off", "Sends off command to bound Group" },
		{ &Group::ToggleCommandHandler, "toggle", "Sends toggle command to bound Group" }
	};

	static const shell_command_t sSwitchCommand = { &SwitchCommandHandler, "switch",
							"Light-switch commands. Usage: switch [onoff|groups]" };

	sShellSwitchGroupsOnOffSubCommands.RegisterCommands(sSwichGroupsOnOffSubCommands,
							    MATTER_ARRAY_SIZE(sSwichGroupsOnOffSubCommands));
	sShellSwitchOnOffSubCommands.RegisterCommands(sSwitchOnOffSubCommands,
						      MATTER_ARRAY_SIZE(sSwitchOnOffSubCommands));
	sShellSwitchGroupsSubCommands.RegisterCommands(sSwitchGroupsSubCommands,
						       MATTER_ARRAY_SIZE(sSwitchGroupsSubCommands));
	sShellSwitchSubCommands.RegisterCommands(sSwitchSubCommands, MATTER_ARRAY_SIZE(sSwitchSubCommands));

	Engine::Root().RegisterCommands(&sSwitchCommand, 1);
}

} /* namespace SwitchCommands */
#endif
```

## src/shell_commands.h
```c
/*
 * Copyright (c) 2022 Nordic Semiconductor ASA
 *
 * SPDX-License-Identifier: LicenseRef-Nordic-5-Clause
 */

#pragma once

#ifdef CONFIG_CHIP_LIB_SHELL
#include <lib/core/CHIPError.h>
#include <lib/shell/Engine.h>
#include <lib/shell/commands/Help.h>

namespace SwitchCommands
{
void RegisterSwitchCommands();

} /* namespace SwitchCommands */

#endif
```
